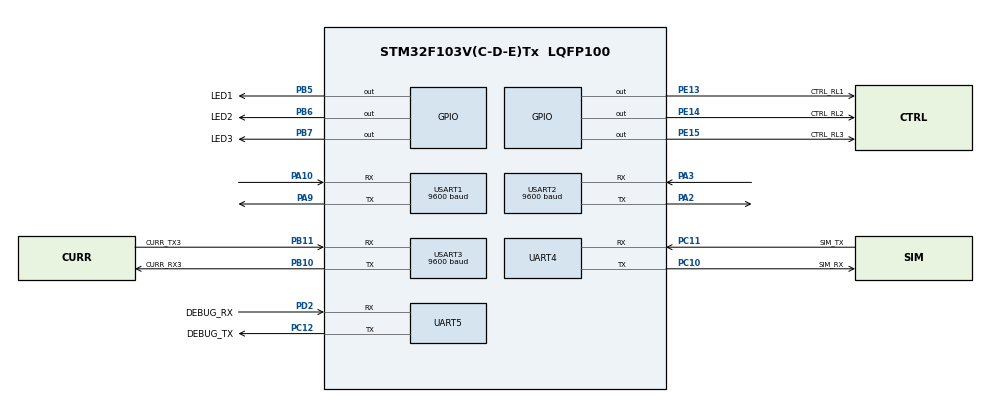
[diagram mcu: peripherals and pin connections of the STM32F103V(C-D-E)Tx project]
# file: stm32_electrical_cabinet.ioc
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Mcu.Family=STM32F1
Mcu.Name=STM32F103V(C-D-E)Tx
Mcu.Package=LQFP100
NVIC.PriorityGroup=NVIC_PRIORITYGROUP_4
NVIC.UART4_IRQn=true\:14\:0\:true\:false\:true\:true\:true\:true
NVIC.UART5_IRQn=true\:15\:0\:true\:false\:true\:true\:true\:true
NVIC.USART1_IRQn=true\:13\:0\:true\:false\:true\:true\:true\:true
NVIC.USART2_IRQn=true\:13\:0\:true\:false\:true\:true\:true\:true
NVIC.USART3_IRQn=true\:13\:0\:true\:false\:true\:true\:true\:true
OSC_IN.Mode=HSE-External-Oscillator
OSC_IN.Signal=RCC_OSC_IN
OSC_OUT.Mode=HSE-External-Oscillator
OSC_OUT.Signal=RCC_OSC_OUT
PA10.Mode=Asynchronous
PA10.Signal=USART1_RX
PA13.Mode=Serial_Wire
PA13.Signal=SYS_JTMS-SWDIO
PA14.Mode=Serial_Wire
PA14.Signal=SYS_JTCK-SWCLK
PA2.Mode=Asynchronous
PA2.Signal=USART2_TX
PA3.Mode=Asynchronous
PA3.Signal=USART2_RX
PA9.Mode=Asynchronous
PA9.Signal=USART1_TX
PB10.GPIO_Label=CURR_RX3
PB10.Mode=Asynchronous
PB10.Signal=USART3_TX
PB11.GPIO_Label=CURR_TX3
PB11.Mode=Asynchronous
PB11.Signal=USART3_RX
PB5.GPIO_Label=LED1
PB5.Signal=GPIO_Output
PB6.GPIO_Label=LED2
PB6.Signal=GPIO_Output
PB7.GPIO_Label=LED3
PB7.Signal=GPIO_Output
PC10.GPIO_Label=SIM_RX
PC10.Mode=Asynchronous
PC10.Signal=UART4_TX
PC11.GPIO_Label=SIM_TX
PC11.Mode=Asynchronous
PC11.Signal=UART4_RX
PC12.GPIO_Label=DEBUG_TX
PC12.Mode=Asynchronous
PC12.Signal=UART5_TX
PD2.GPIO_Label=DEBUG_RX
PD2.Mode=Asynchronous
PD2.Signal=UART5_RX
PE13.GPIO_Label=CTRL_RL1
PE13.Signal=GPIO_Output
PE14.GPIO_Label=CTRL_RL2
PE14.Signal=GPIO_Output
PE15.GPIO_Label=CTRL_RL3
PE15.Signal=GPIO_Output
ProjectManager.HeapSize=0x3000
ProjectManager.StackSize=0x3000
ProjectManager.TargetToolchain=STM32CubeIDE
RCC.AHBFreq_Value=72000000
RCC.APB1CLKDivider=RCC_HCLK_DIV2
RCC.APB1Freq_Value=36000000
RCC.APB1TimFreq_Value=72000000
RCC.APB2Freq_Value=72000000
RCC.APB2TimFreq_Value=72000000
RCC.HCLKFreq_Value=72000000
RCC.PLLMUL=RCC_PLL_MUL9
RCC.PLLSourceVirtual=RCC_PLLSOURCE_HSE
RCC.SYSCLKFreq_VALUE=72000000
RCC.SYSCLKSource=RCC_SYSCLKSOURCE_PLLCLK
RCC.USBFreq_Value=72000000
UART4.VirtualMode=Asynchronous
UART5.VirtualMode=Asynchronous
USART1.BaudRate=9600
USART1.VirtualMode=VM_ASYNC
USART2.BaudRate=9600
USART2.VirtualMode=VM_ASYNC
USART3.BaudRate=9600
USART3.VirtualMode=VM_ASYNC
VP_RTC_VS_RTC_Activate.Mode=RTC_Enabled
board=custom

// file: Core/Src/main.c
/* USER CODE BEGIN Header */
/**
  ******************************************************************************
  * @file           : main.c
  * @brief          : Main program body
  ******************************************************************************
  * @attention
  *
  * Copyright (c) 2024 STMicroelectronics.
  * All rights reserved.
  *
  * This software is licensed under terms that can be found in the LICENSE file
  * in the root directory of this software component.
  * If no LICENSE file comes with this software, it is provided AS-IS.
  *
  ******************************************************************************
  */
/* USER CODE END Header */
#include "main.h"

/* USER CODE BEGIN Includes */
#include "sv_power.h"
#include "cabinet_app.h"
/* USER CODE END Includes */

RTC_HandleTypeDef hrtc;

UART_HandleTypeDef huart4;
UART_HandleTypeDef huart5;
UART_HandleTypeDef huart1;
UART_HandleTypeDef huart2;
UART_HandleTypeDef huart3;

void SystemClock_Config(void);
static void MX_GPIO_Init(void);
static void MX_UART4_Init(void);
static void MX_UART5_Init(void);
static void MX_USART1_UART_Init(void);
static void MX_USART2_UART_Init(void);
static void MX_USART3_UART_Init(void);
static void MX_RTC_Init(void);
/* USER CODE BEGIN PFP */
int64_t get_tick_count();
/* USER CODE END PFP */

/* USER CODE BEGIN 0 */
volatile int64_t sysTick = 0;
int64_t get_tick_count(){
	return (int64_t)HAL_GetTick();
}
/* USER CODE END 0 */

int main(void)
{

  /* MCU Configuration--------------------------------------------------------*/

  /* Reset of all peripherals, Initializes the Flash interface and the Systick. */
  HAL_Init();

  /* Configure the system clock */
  SystemClock_Config();

  /* Initialize all configured peripherals */
  MX_GPIO_Init();
  MX_UART4_Init();
  MX_UART5_Init();
  MX_USART1_UART_Init();
  MX_USART2_UART_Init();
  MX_USART3_UART_Init();
  MX_RTC_Init();
  /* USER CODE BEGIN 2 */
  cabinet_app_init();

  __enable_irq();
  __enable_fault_irq();

  cabinet_app_process();

  /* USER CODE END 2 */

  /* Infinite loop */
  while (1)
  {

  }
}

void SystemClock_Config(void)
{
  LL_FLASH_SetLatency(LL_FLASH_LATENCY_2);
  while(LL_FLASH_GetLatency()!= LL_FLASH_LATENCY_2)
  {
  }
  LL_RCC_HSE_Enable();

   /* Wait till HSE is ready */
  while(LL_RCC_HSE_IsReady() != 1)
  {

  }
  LL_RCC_LSI_Enable();

   /* Wait till LSI is ready */
  while(LL_RCC_LSI_IsReady() != 1)
  {

  }
  LL_PWR_EnableBkUpAccess();
  if(LL_RCC_GetRTCClockSource() != LL_RCC_RTC_CLKSOURCE_LSI)
  {
    LL_RCC_ForceBackupDomainReset();
    LL_RCC_ReleaseBackupDomainReset();
    LL_RCC_SetRTCClockSource(LL_RCC_RTC_CLKSOURCE_LSI);
  }
  LL_RCC_EnableRTC();
  LL_RCC_PLL_ConfigDomain_SYS(LL_RCC_PLLSOURCE_HSE_DIV_1, LL_RCC_PLL_MUL_9);
  LL_RCC_PLL_Enable();

   /* Wait till PLL is ready */
  while(LL_RCC_PLL_IsReady() != 1)
  {

  }
  LL_RCC_SetAHBPrescaler(LL_RCC_SYSCLK_DIV_1);
  LL_RCC_SetAPB1Prescaler(LL_RCC_APB1_DIV_2);
  LL_RCC_SetAPB2Prescaler(LL_RCC_APB2_DIV_1);
  LL_RCC_SetSysClkSource(LL_RCC_SYS_CLKSOURCE_PLL);

   /* Wait till System clock is ready */
  while(LL_RCC_GetSysClkSource() != LL_RCC_SYS_CLKSOURCE_STATUS_PLL)
  {

  }
  LL_SetSystemCoreClock(72000000);

   /* Update the time base */
  if (HAL_InitTick (TICK_INT_PRIORITY) != HAL_OK)
  {
    Error_Handler();
  }
}

static void MX_RTC_Init(void)
{

  /** Initialize RTC Only
  */
  hrtc.Instance = RTC;
  hrtc.Init.AsynchPrediv = RTC_AUTO_1_SECOND;
  hrtc.Init.OutPut = RTC_OUTPUTSOURCE_ALARM;
  if (HAL_RTC_Init(&hrtc) != HAL_OK)
  {
    Error_Handler();
  }

}

static void MX_UART4_Init(void)
{

  huart4.Instance = UART4;
  huart4.Init.BaudRate = 115200;
  huart4.Init.WordLength = UART_WORDLENGTH_8B;
  huart4.Init.StopBits = UART_STOPBITS_1;
  huart4.Init.Parity = UART_PARITY_NONE;
  huart4.Init.Mode = UART_MODE_TX_RX;
  huart4.Init.HwFlowCtl = UART_HWCONTROL_NONE;
  huart4.Init.OverSampling = UART_OVERSAMPLING_16;
  if (HAL_UART_Init(&huart4) != HAL_OK)
  {
    Error_Handler();
  }

}

static void MX_UART5_Init(void)
{

  huart5.Instance = UART5;
  huart5.Init.BaudRate = 115200;
  huart5.Init.WordLength = UART_WORDLENGTH_8B;
  huart5.Init.StopBits = UART_STOPBITS_1;
  huart5.Init.Parity = UART_PARITY_NONE;
  huart5.Init.Mode = UART_MODE_TX_RX;
  huart5.Init.HwFlowCtl = UART_HWCONTROL_NONE;
  huart5.Init.OverSampling = UART_OVERSAMPLING_16;
  if (HAL_UART_Init(&huart5) != HAL_OK)
  {
    Error_Handler();
  }

}

static void MX_USART1_UART_Init(void)
{

  huart1.Instance = USART1;
  huart1.Init.BaudRate = 115200;
  huart1.Init.WordLength = UART_WORDLENGTH_8B;
  huart1.Init.StopBits = UART_STOPBITS_1;
  huart1.Init.Parity = UART_PARITY_NONE;
  huart1.Init.Mode = UART_MODE_TX_RX;
  huart1.Init.HwFlowCtl = UART_HWCONTROL_NONE;
  huart1.Init.OverSampling = UART_OVERSAMPLING_16;
  if (HAL_UART_Init(&huart1) != HAL_OK)
  {
    Error_Handler();
  }

}

static void MX_USART2_UART_Init(void)
{

  huart2.Instance = USART2;
  huart2.Init.BaudRate = 115200;
  huart2.Init.WordLength = UART_WORDLENGTH_8B;
  huart2.Init.StopBits = UART_STOPBITS_1;
  huart2.Init.Parity = UART_PARITY_NONE;
  huart2.Init.Mode = UART_MODE_TX_RX;
  huart2.Init.HwFlowCtl = UART_HWCONTROL_NONE;
  huart2.Init.OverSampling = UART_OVERSAMPLING_16;
  if (HAL_UART_Init(&huart2) != HAL_OK)
  {
    Error_Handler();
  }

}

static void MX_USART3_UART_Init(void)
{

  huart3.Instance = USART3;
  huart3.Init.BaudRate = 115200;
  huart3.Init.WordLength = UART_WORDLENGTH_8B;
  huart3.Init.StopBits = UART_STOPBITS_1;
  huart3.Init.Parity = UART_PARITY_NONE;
  huart3.Init.Mode = UART_MODE_TX_RX;
  huart3.Init.HwFlowCtl = UART_HWCONTROL_NONE;
  huart3.Init.OverSampling = UART_OVERSAMPLING_16;
  if (HAL_UART_Init(&huart3) != HAL_OK)
  {
    Error_Handler();
  }

}

static void MX_GPIO_Init(void)
{
  GPIO_InitTypeDef GPIO_InitStruct = {0};

  /* GPIO Ports Clock Enable */
  __HAL_RCC_GPIOA_CLK_ENABLE();
  __HAL_RCC_GPIOE_CLK_ENABLE();
  __HAL_RCC_GPIOB_CLK_ENABLE();
  __HAL_RCC_GPIOC_CLK_ENABLE();
  __HAL_RCC_GPIOD_CLK_ENABLE();

  /*Configure GPIO pin Output Level */
  HAL_GPIO_WritePin(GPIOE, CTRL_RL1_Pin|CTRL_RL2_Pin|CTRL_RL3_Pin, GPIO_PIN_RESET);

  /*Configure GPIO pin Output Level */
  HAL_GPIO_WritePin(GPIOB, LED1_Pin|LED2_Pin|LED3_Pin, GPIO_PIN_RESET);

  /*Configure GPIO pins : CTRL_RL1_Pin CTRL_RL2_Pin CTRL_RL3_Pin */
  GPIO_InitStruct.Pin = CTRL_RL1_Pin|CTRL_RL2_Pin|CTRL_RL3_Pin;
  GPIO_InitStruct.Mode = GPIO_MODE_OUTPUT_PP;
  GPIO_InitStruct.Pull = GPIO_NOPULL;
  GPIO_InitStruct.Speed = GPIO_SPEED_FREQ_LOW;
  HAL_GPIO_Init(GPIOE, &GPIO_InitStruct);

  /*Configure GPIO pins : LED1_Pin LED2_Pin LED3_Pin */
  GPIO_InitStruct.Pin = LED1_Pin|LED2_Pin|LED3_Pin;
  GPIO_InitStruct.Mode = GPIO_MODE_OUTPUT_PP;
  GPIO_InitStruct.Pull = GPIO_NOPULL;
  GPIO_InitStruct.Speed = GPIO_SPEED_FREQ_LOW;
  HAL_GPIO_Init(GPIOB, &GPIO_InitStruct);

}

/* USER CODE BEGIN 4 */
//void HAL_TIM_PeriodElapsedCallback(TIM_HandleTypeDef *htim) {
//	if (htim->Instance == TIM6){
//		sysTick++;
//	}
//}
/* USER CODE END 4 */

void Error_Handler(void)
{
  __disable_irq();
  while (1)
  {
  }
}
